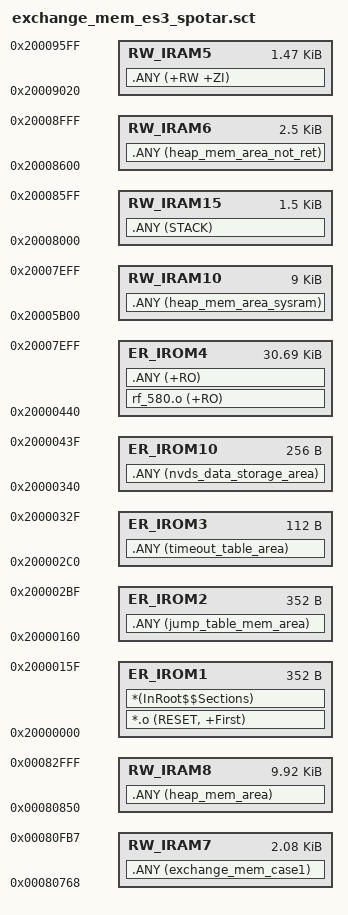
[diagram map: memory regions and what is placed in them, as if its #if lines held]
#! armcc -E -I./ --cpu Cortex-M0

#include "da14580_config.h"

; *************************************************************
; *** Scatter-Loading Description File generated by uVision ***
; *************************************************************

LR_IROM1 0x20000000 0x00000160 {  ; load region size_region
    ER_IROM1 0x20000000 0x00000160  {  ; load address = execution address
        *.o (RESET, +First)
        *(InRoot$$Sections)
    }
}
 
LR_IROM2  0x20000160 0x00160 {
    ER_IROM2 0x20000160 0x00160  {
        .ANY (jump_table_mem_area) 	
    }
}

LR_IROM3 0x200002C0 0x070 {
    ER_IROM3 0x200002C0 0x070  {
        .ANY (timeout_table_area)
    }
}

LR_IROM10 0x20000340 0x0100 {
    ER_IROM10 0x20000340 0x0100  {
        .ANY (nvds_data_storage_area)
    }
}

LR_IROM4  0x20000440 0x7ac0 {
    ER_IROM4 0x20000440 0x7ac0  {
;        rf_ripple.o (+RO)
        rf_580.o (+RO)
        .ANY (+RO)   	
    }
#if (BLE_CONNECTION_MAX_USER > 4) 
    RW_IRAM10 0x20005b00 0x00002400  {
        .ANY (heap_mem_area_sysram)
    }  
#endif  
}  

LR_IRAM5  0x20008000 0x00002800 {
  
    RW_IRAM6 0x20008600 0x0000a00  {
        .ANY (heap_mem_area_not_ret)    
    }
    
    RW_IRAM15 0x20008000 0x00000600 {  ; RW data
        .ANY (STACK)
    }

#if DEVELOPMENT__NO_OTP
    RW_IRAM5 0x20009020 0x000005e0   {  ; RW data
        .ANY (+RW +ZI)
    }
#endif

;    RW_IRAM9 0x20009600 0x100   {  	    ; 0x20009600 - 0x20009700 SYSRAM patch data buffer
;        app_spotar.o (spota_patch_data_area) 
;	}
    
    RW_IRAM7 0x000080768 0x00000850  {
        .ANY (exchange_mem_case1) 
    }

#ifdef CFG_EXT_SLEEP
    RW_IRAM8 0x000080850 0x000027B0  {
        .ANY (heap_mem_area)
    }
#else
    RW_IRAM8 0x000080850 0x000017B0  {
        .ANY (heap_mem_area)
    }
#endif  
}

